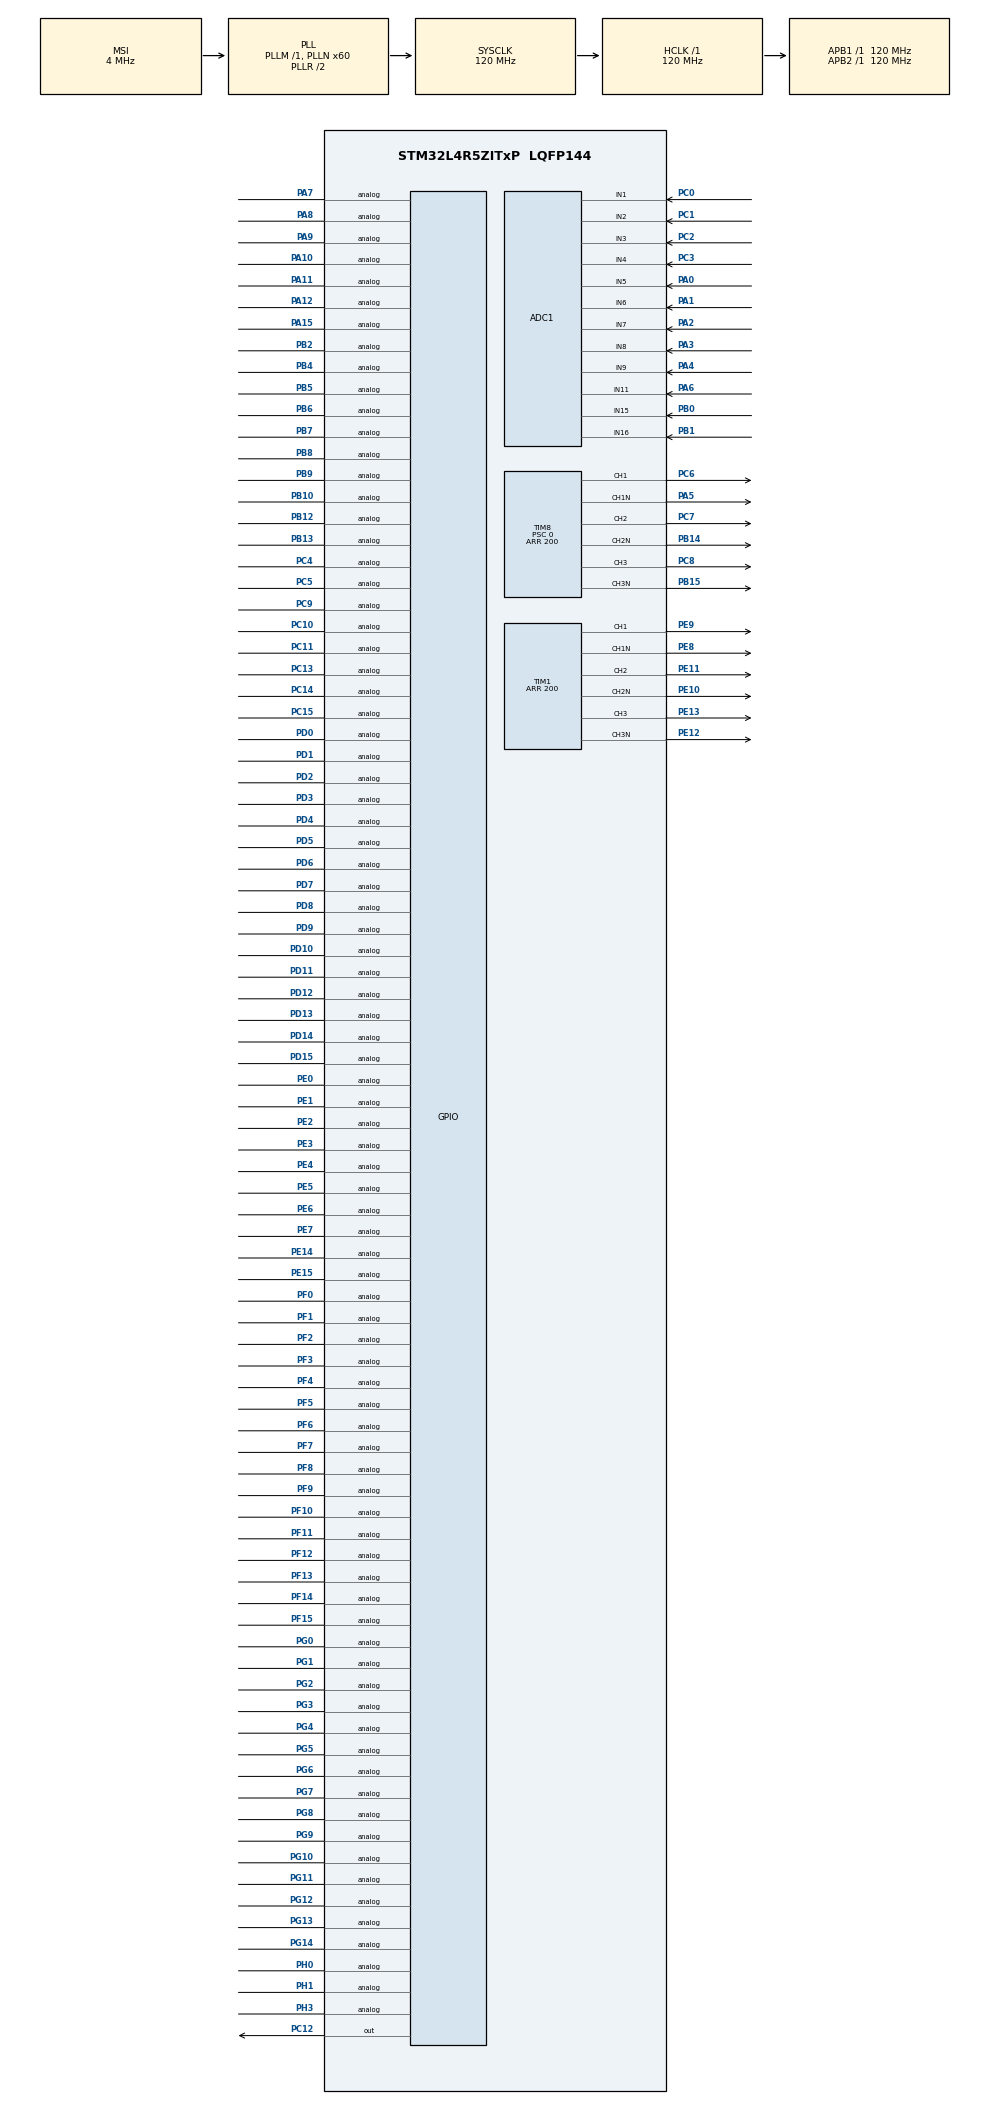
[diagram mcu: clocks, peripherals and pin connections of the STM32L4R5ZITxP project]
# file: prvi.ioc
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ADC1.Channel-0\#ChannelRegularConversion=ADC_CHANNEL_4
ADC1.Channel-1\#ChannelRegularConversion=ADC_CHANNEL_2
ADC1.Channel-2\#ChannelRegularConversion=ADC_CHANNEL_5
ADC1.Channel-3\#ChannelRegularConversion=ADC_CHANNEL_3
ADC1.Channel-4\#ChannelRegularConversion=ADC_CHANNEL_1
ADC1.ContinuousConvMode=ENABLE
ADC1.EOCSelection=ADC_EOC_SEQ_CONV
ADC1.EnableInjectedConversion=DISABLE
ADC1.ExternalTrigConv=ADC_EXTERNALTRIG_T1_TRGO2
ADC1.NbrOfConversion=5
ADC1.NbrOfConversionFlag=1
ADC1.OffsetNumber-0\#ChannelRegularConversion=ADC_OFFSET_NONE
ADC1.OffsetNumber-1\#ChannelRegularConversion=ADC_OFFSET_NONE
ADC1.OffsetNumber-2\#ChannelRegularConversion=ADC_OFFSET_NONE
ADC1.OffsetNumber-3\#ChannelRegularConversion=ADC_OFFSET_NONE
ADC1.OffsetNumber-4\#ChannelRegularConversion=ADC_OFFSET_NONE
ADC1.Overrun=ADC_OVR_DATA_OVERWRITTEN
ADC1.Rank-0\#ChannelRegularConversion=1
ADC1.Rank-1\#ChannelRegularConversion=2
ADC1.Rank-2\#ChannelRegularConversion=3
ADC1.Rank-3\#ChannelRegularConversion=4
ADC1.Rank-4\#ChannelRegularConversion=5
ADC1.Rank1_Channel=ADC_CHANNEL_2
ADC1.Rank2_Channel=ADC_CHANNEL_3
ADC1.Rank3_Channel=ADC_CHANNEL_4
ADC1.Rank4_Channel=ADC_CHANNEL_5
ADC1.SamplingTime-0\#ChannelRegularConversion=ADC_SAMPLETIME_2CYCLES_5
ADC1.SamplingTime-1\#ChannelRegularConversion=ADC_SAMPLETIME_2CYCLES_5
ADC1.SamplingTime-2\#ChannelRegularConversion=ADC_SAMPLETIME_6CYCLES_5
ADC1.SamplingTime-3\#ChannelRegularConversion=ADC_SAMPLETIME_6CYCLES_5
ADC1.SamplingTime-4\#ChannelRegularConversion=ADC_SAMPLETIME_6CYCLES_5
ADC1.master=1
Dma.ADC1.0.Direction=DMA_PERIPH_TO_MEMORY
Dma.ADC1.0.EventEnable=ENABLE
Dma.ADC1.0.Instance=DMA1_Channel1
Dma.ADC1.0.MemDataAlignment=DMA_MDATAALIGN_WORD
Dma.ADC1.0.MemInc=DMA_MINC_ENABLE
Dma.ADC1.0.Mode=DMA_NORMAL
Dma.ADC1.0.PeriphDataAlignment=DMA_PDATAALIGN_HALFWORD
Dma.ADC1.0.PeriphInc=DMA_PINC_DISABLE
Dma.ADC1.0.Polarity=HAL_DMAMUX_REQUEST_GEN_RISING
Dma.ADC1.0.Priority=DMA_PRIORITY_LOW
Dma.ADC1.0.RequestNumber=1
Dma.ADC1.0.SignalID=NONE
Dma.ADC1.0.SyncEnable=DISABLE
Dma.ADC1.0.SyncPolarity=HAL_DMAMUX_SYNC_NO_EVENT
Dma.ADC1.0.SyncRequestNumber=1
Dma.ADC1.0.SyncSignalID=NONE
Dma.Request0=ADC1
Mcu.Family=STM32L4
Mcu.Name=STM32L4R5ZITxP
Mcu.Package=LQFP144
NVIC.DMA1_Channel1_IRQn=true\:0\:0\:false\:false\:true\:false\:true
NVIC.DMAMUX1_OVR_IRQn=true\:0\:0\:false\:false\:true\:false\:false
NVIC.PriorityGroup=NVIC_PRIORITYGROUP_4
PA0.Signal=ADCx_IN5
PA1.Signal=ADCx_IN6
PA10.Signal=GPIO_Analog
PA11.Signal=GPIO_Analog
PA12.Signal=GPIO_Analog
PA13\ (JTMS/SWDIO).Mode=Trace_Asynchronous_SW
PA13\ (JTMS/SWDIO).Signal=SYS_JTMS-SWDIO
PA14\ (JTCK/SWCLK).Mode=Trace_Asynchronous_SW
PA14\ (JTCK/SWCLK).Signal=SYS_JTCK-SWCLK
PA15\ (JTDI).Signal=GPIO_Analog
PA2.Signal=ADCx_IN7
PA3.Signal=ADCx_IN8
PA4.Signal=ADCx_IN9
PA5.Mode=PWM Generation1 CH1 CH1N
PA5.Signal=TIM8_CH1N
PA6.Signal=ADCx_IN11
PA7.Signal=GPIO_Analog
PA8.Signal=GPIO_Analog
PA9.Signal=GPIO_Analog
PB0.Signal=ADCx_IN15
PB1.Signal=ADCx_IN16
PB10.Signal=GPIO_Analog
PB12.Signal=GPIO_Analog
PB13.Signal=GPIO_Analog
PB14.Mode=PWM Generation2 CH2 CH2N
PB14.Signal=TIM8_CH2N
PB15.Mode=PWM Generation3 CH3 CH3N
PB15.Signal=TIM8_CH3N
PB2.Signal=GPIO_Analog
PB3\ (JTDO/TRACESWO).Mode=Trace_Asynchronous_SW
PB3\ (JTDO/TRACESWO).Signal=SYS_JTDO-SWO
PB4\ (NJTRST).Signal=GPIO_Analog
PB5.Signal=GPIO_Analog
PB6.Signal=GPIO_Analog
PB7.Signal=GPIO_Analog
PB8.Signal=GPIO_Analog
PB9.Signal=GPIO_Analog
PC0.Signal=ADCx_IN1
PC1.Signal=ADCx_IN2
PC10.Signal=GPIO_Analog
PC11.Signal=GPIO_Analog
PC12.GPIO_Speed=GPIO_SPEED_FREQ_VERY_HIGH
PC12.Signal=GPIO_Output
PC13.Signal=GPIO_Analog
PC14-OSC32_IN\ (PC14).Signal=GPIO_Analog
PC15-OSC32_OUT\ (PC15).Signal=GPIO_Analog
PC2.Signal=ADCx_IN3
PC3.Signal=ADCx_IN4
PC4.Signal=GPIO_Analog
PC5.Signal=GPIO_Analog
PC6.Signal=S_TIM8_CH1
PC7.Signal=S_TIM8_CH2
PC8.Signal=S_TIM8_CH3
PC9.Signal=GPIO_Analog
PD0.Signal=GPIO_Analog
PD1.Signal=GPIO_Analog
PD10.Signal=GPIO_Analog
PD11.Signal=GPIO_Analog
PD12.Signal=GPIO_Analog
PD13.Signal=GPIO_Analog
PD14.Signal=GPIO_Analog
PD15.Signal=GPIO_Analog
PD2.Signal=GPIO_Analog
PD3.Signal=GPIO_Analog
PD4.Signal=GPIO_Analog
PD5.Signal=GPIO_Analog
PD6.Signal=GPIO_Analog
PD7.Signal=GPIO_Analog
PD8.Signal=GPIO_Analog
PD9.Signal=GPIO_Analog
PE0.Signal=GPIO_Analog
PE1.Signal=GPIO_Analog
PE10.Mode=PWM Generation2 CH2 CH2N
PE10.Signal=TIM1_CH2N
PE11.Signal=S_TIM1_CH2
PE12.Mode=PWM Generation3 CH3 CH3N
PE12.Signal=TIM1_CH3N
PE13.Signal=S_TIM1_CH3
PE14.Signal=GPIO_Analog
PE15.Signal=GPIO_Analog
PE2.Signal=GPIO_Analog
PE3.Signal=GPIO_Analog
PE4.Signal=GPIO_Analog
PE5.Signal=GPIO_Analog
PE6.Signal=GPIO_Analog
PE7.Signal=GPIO_Analog
PE8.Mode=PWM Generation1 CH1 CH1N
PE8.Signal=TIM1_CH1N
PE9.Signal=S_TIM1_CH1
PF0.Signal=GPIO_Analog
PF1.Signal=GPIO_Analog
PF10.Signal=GPIO_Analog
PF11.Signal=GPIO_Analog
PF12.Signal=GPIO_Analog
PF13.Signal=GPIO_Analog
PF14.Signal=GPIO_Analog
PF15.Signal=GPIO_Analog
PF2.Signal=GPIO_Analog
PF3.Signal=GPIO_Analog
PF4.Signal=GPIO_Analog
PF5.Signal=GPIO_Analog
PF6.Signal=GPIO_Analog
PF7.Signal=GPIO_Analog
PF8.Signal=GPIO_Analog
PF9.Signal=GPIO_Analog
PG0.Signal=GPIO_Analog
PG1.Signal=GPIO_Analog
PG10.Signal=GPIO_Analog
PG11.Signal=GPIO_Analog
PG12.Signal=GPIO_Analog
PG13.Signal=GPIO_Analog
PG14.Signal=GPIO_Analog
PG2.Signal=GPIO_Analog
PG3.Signal=GPIO_Analog
PG4.Signal=GPIO_Analog
PG5.Signal=GPIO_Analog
PG6.Signal=GPIO_Analog
PG7.Signal=GPIO_Analog
PG8.Signal=GPIO_Analog
PG9.Signal=GPIO_Analog
PH0-OSC_IN\ (PH0).Signal=GPIO_Analog
PH1-OSC_OUT\ (PH1).Signal=GPIO_Analog
PH3-BOOT0.Signal=GPIO_Analog
ProjectManager.HeapSize=0x200
ProjectManager.StackSize=0x400
ProjectManager.TargetToolchain=STM32CubeIDE
RCC.ADCFreq_Value=74000000
RCC.AHBFreq_Value=120000000
RCC.APB1Freq_Value=120000000
RCC.APB1TimFreq_Value=120000000
RCC.APB2Freq_Value=120000000
RCC.APB2TimFreq_Value=120000000
RCC.CortexFreq_Value=120000000
RCC.HCLKFreq_Value=120000000
RCC.HSE_VALUE=8000000
RCC.HSI48_VALUE=48000000
RCC.HSI_VALUE=16000000
RCC.LSE_VALUE=32768
RCC.MSI_VALUE=4000000
RCC.PLLN=60
RCC.PLLSAI1N=37
RCC.SYSCLKFreq_VALUE=120000000
RCC.SYSCLKSource=RCC_SYSCLKSOURCE_PLLCLK
RCC.USBFreq_Value=74000000
RCC.VCOOutputFreq_Value=240000000
SH.ADCx_IN1.0=ADC1_IN1,IN1-Single-Ended
SH.ADCx_IN11.0=ADC1_IN11,IN11-Single-Ended
SH.ADCx_IN15.0=ADC1_IN15,IN15-Single-Ended
SH.ADCx_IN16.0=ADC1_IN16,IN16-Single-Ended
SH.ADCx_IN2.0=ADC1_IN2,IN2-Single-Ended
SH.ADCx_IN3.0=ADC1_IN3,IN3-Single-Ended
SH.ADCx_IN4.0=ADC1_IN4,IN4-Single-Ended
SH.ADCx_IN5.0=ADC1_IN5,IN5-Single-Ended
SH.ADCx_IN6.0=ADC1_IN6,IN6-Single-Ended
SH.ADCx_IN7.0=ADC1_IN7,IN7-Single-Ended
SH.ADCx_IN8.0=ADC1_IN8,IN8-Single-Ended
SH.ADCx_IN9.0=ADC1_IN9,IN9-Single-Ended
SH.S_TIM1_CH1.0=TIM1_CH1,PWM Generation1 CH1 CH1N
SH.S_TIM1_CH2.0=TIM1_CH2,PWM Generation2 CH2 CH2N
SH.S_TIM1_CH3.0=TIM1_CH3,PWM Generation3 CH3 CH3N
SH.S_TIM8_CH1.0=TIM8_CH1,PWM Generation1 CH1 CH1N
SH.S_TIM8_CH2.0=TIM8_CH2,PWM Generation2 CH2 CH2N
SH.S_TIM8_CH3.0=TIM8_CH3,PWM Generation3 CH3 CH3N
TIM1.AutoReloadPreload=TIM_AUTORELOAD_PRELOAD_ENABLE
TIM1.Channel-PWM\ Generation1\ CH1\ CH1N=TIM_CHANNEL_1
TIM1.Channel-PWM\ Generation2\ CH2\ CH2N=TIM_CHANNEL_2
TIM1.Channel-PWM\ Generation3\ CH3\ CH3N=TIM_CHANNEL_3
TIM1.CounterMode=TIM_COUNTERMODE_CENTERALIGNED2
TIM1.DeadTime=12
TIM1.OCFastMode_PWM-PWM\ Generation1\ CH1\ CH1N=TIM_OCFAST_ENABLE
TIM1.OCFastMode_PWM-PWM\ Generation2\ CH2\ CH2N=TIM_OCFAST_ENABLE
TIM1.OCFastMode_PWM-PWM\ Generation3\ CH3\ CH3N=TIM_OCFAST_ENABLE
TIM1.OCMode_PWM-PWM\ Generation1\ CH1\ CH1N=TIM_OCMODE_PWM1
TIM1.OCMode_PWM-PWM\ Generation2\ CH2\ CH2N=TIM_OCMODE_PWM1
TIM1.OCMode_PWM-PWM\ Generation3\ CH3\ CH3N=TIM_OCMODE_PWM1
TIM1.Period=200
TIM1.Pulse-PWM\ Generation1\ CH1\ CH1N=40
TIM1.Pulse-PWM\ Generation2\ CH2\ CH2N=160
TIM1.Pulse-PWM\ Generation3\ CH3\ CH3N=110
TIM1.TIM_MasterOutputTrigger2=TIM_TRGO2_UPDATE
TIM8.AutoReloadPreload=TIM_AUTORELOAD_PRELOAD_ENABLE
TIM8.Channel-PWM\ Generation1\ CH1\ CH1N=TIM_CHANNEL_1
TIM8.Channel-PWM\ Generation2\ CH2\ CH2N=TIM_CHANNEL_2
TIM8.Channel-PWM\ Generation3\ CH3\ CH3N=TIM_CHANNEL_3
TIM8.CounterMode=TIM_COUNTERMODE_CENTERALIGNED2
TIM8.DeadTime=12
TIM8.OCFastMode_PWM-PWM\ Generation1\ CH1\ CH1N=TIM_OCFAST_ENABLE
TIM8.OCFastMode_PWM-PWM\ Generation2\ CH2\ CH2N=TIM_OCFAST_ENABLE
TIM8.OCFastMode_PWM-PWM\ Generation3\ CH3\ CH3N=TIM_OCFAST_ENABLE
TIM8.Period=200
TIM8.Prescaler=0
TIM8.Pulse-PWM\ Generation1\ CH1\ CH1N=150
TIM8.Pulse-PWM\ Generation2\ CH2\ CH2N=250
TIM8.Pulse-PWM\ Generation3\ CH3\ CH3N=167
VP_TIM1_VS_ClockSourceINT.Mode=Internal
board=NUCLEO-L4R5ZI-P

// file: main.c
/* USER CODE BEGIN Header */

/*
 * drolja sa frekvencijom regulacije 25KHz za ulazne i bat, a 12.5KHz za izlazne
 * svaka prekidna je podeljena na 3 dela: priprema ADC, usrednjavanje izmerenog, regulacija
 * prekidnu uvek zove DMA, a koja se prekidna izvrsava se odlucuje pomocu brojaca dma_cnt
 */

/* USER CODE END Header */

#include "main.h"

ADC_HandleTypeDef hadc1;
DMA_HandleTypeDef hdma_adc1;

TIM_HandleTypeDef htim1;
TIM_HandleTypeDef htim8;

/* USER CODE BEGIN PV */

volatile int dma_cnt = 0, i1=0, i2=0;
volatile float v_pv1, i_pv1, vold_pv1 = 0, iold_pv1 = 0, e_pv1, eold_pv1 = 0, d_pv1, dold_pv1 = 0.8, p_pv1, pold_pv1 = 0;			//za prvi ulazni buck
volatile float v_pv2, i_pv2, vold_pv2 = 0, iold_pv2 = 0, e_pv2, eold_pv2 = 0, d_pv2, dold_pv2 = 0.8, p_pv2, pold_pv2 = 0;			//za drugi ulazni buck
volatile float v_dc;																												//za link
volatile float v_5v, e_5v, eold_5v = 0, d_5v, dold_5v = 0.835;																		//za 5v izlaz
volatile float v_3v3, e_3v3, eold_3v3 = 0, d_3v3, dold_3v3 = 0.55;																	//za 3v3 izlaz
volatile float v_bat, i_bat, e_bat, eold_bat = 0, d_bat, dold_bat = 0.75;															//za bateriju

volatile int zaokruzi;
volatile float step;
const float step_mppt = 0.0002;

//koeficijenti za razdelnike - svi podlozni promenama
const float v_dc_coef = 0.0026333;			//0-9V
const float v_pv_coef = 0.00629;			//0-25V
const float i_pv_coef = 0.0004884;			//?????
const float v_3v3_coef = 0.0018156;			//0-6.6V
const float v_5v_coef = 0.0022055;			//0-8V

//koeficijenti za regulaciju
const float reg1_3v3 = 0.002;
const float reg2_3v3 = 0.001;
const float reg1_5v = 0.002;
const float reg2_5v = 0.001;
const float reg1_bat = 0.002;
const float reg2_bat = 0.001;
const float reg_pv = 0.005;				//za pv pomeranje
const float ref_3v3 = 3.3;					//referenca koja ne moze da se upise sa vmov

//bufferi za DMA:
uint32_t pv1_buffer[40], pv2_buffer[40], bat_buffer[24], out3v3_buffer[16], out5v_buffer[16];

/* USER CODE END PV */

void SystemClock_Config(void);
static void MX_GPIO_Init(void);
static void MX_DMA_Init(void);
static void MX_ADC1_Init(void);
static void MX_TIM1_Init(void);
static void MX_TIM8_Init(void);

/* USER CODE BEGIN 0 */

void DMA1_Channel1_IRQHandler(void)
{
	if (DMA1 -> ISR & 2) {							//transfer complete se obradjuje
		DMA1 -> IFCR = 2;

		ADC1 -> CR |= 0x10;							//ADC stop (mora OR a ne dodela da se ne bi pojebala kalibracija
		DMA1_Channel1 -> CCR &= 0xFFFFFFFE;			//disable DMA

    	dma_cnt++;									//uvecaj brojac radi pracenja u kojoj si prekidnoj

		while (DMA1_Channel1 -> CCR & 1);			//cekaj disable
		//while (ADC1 -> CR & 4);	//nije neophodno cekati da se adc stopira jer ima dosta instrukcija izmedju

		/* KORISTAN DEO KODA */
		switch (dma_cnt) {								//provera u kojoj smo prekidnoj

		/* pv1 */
		case 1:
		case 5:
			/* priprema sledeceg merenja */
			DMA1_Channel1 -> CMAR = (int) bat_buffer;	//postavi buffer za upis
			DMA1_Channel1 -> CNDTR = 24;				//koliko upisa
			ADC1 -> SQR1 = 0x001C8142;					//kanali 5,8,7 (Udc, Ub, Ib)
			DMA1_Channel1 -> CCR |= 1;					//enable DMA
		    ADC1 -> CR |= 0x4;							//ADC start
			/* kraj pripreme merenja */

			/* usrednjavanje */
			v_dc  = (pv1_buffer[2] + pv1_buffer[7] + pv1_buffer[12] + pv1_buffer[17] + pv1_buffer[22] + pv1_buffer[27] + pv1_buffer[32] + pv1_buffer[37])>>3;
			asm("ldr r0, =v_dc;"
					"ldr r1, [r0];"
			  		"ldr r2, =v_dc_coef;"
			  		"ldr r3, [r2];"
			   		"vmov s2, r1;"
			   		"vmov s4, r3;"
			   		"vmul.f32 s2, s2, s4;"
			   		"vmov r1, s2;"
			   		"str r1, [r0]");
			v_pv1 = (pv1_buffer[1] + pv1_buffer[6] + pv1_buffer[11] + pv1_buffer[16] + pv1_buffer[21] + pv1_buffer[26] + pv1_buffer[31] + pv1_buffer[36])>>3;
			asm("ldr r0, =v_pv1;"
			   		"ldr r1, [r0];"
			  		"ldr r2, =v_pv_coef;"
			   		"ldr r3, [r2];"
			   		"vmov s2, r1;"
			   		"vmov s4, r3;"
			   		"vmul.f32 s2, s2, s4;"
			   		"vmov r1, s2;"
			   		"str r1, [r0]");
			v_pv2 = (pv1_buffer[0] + pv1_buffer[5] + pv1_buffer[10] + pv1_buffer[15] + pv1_buffer[20] + pv1_buffer[25] + pv1_buffer[30] + pv1_buffer[35])>>3;
			asm("ldr r0, =v_pv2;"
			   		"ldr r1, [r0];"
			  		"ldr r2, =v_pv_coef;"
			   		"ldr r3, [r2];"
			   		"vmov s2, r1;"
			   		"vmov s4, r3;"
			   		"vmul.f32 s2, s2, s4;"
			   		"vmov r1, s2;"
			   		"str r1, [r0]");
			i_pv1 = (pv1_buffer[4] + pv1_buffer[9] + pv1_buffer[14] + pv1_buffer[19] + pv1_buffer[24] + pv1_buffer[29] + pv1_buffer[34] + pv1_buffer[39])>>3;
			asm("ldr r0, =i_pv1;"
			   		"ldr r1, [r0];"
			  		"ldr r2, =i_pv_coef;"
			   		"ldr r3, [r2];"
			   		"vmov s2, r1;"
			   		"vmov s4, r3;"
			   		"vmul.f32 s2, s2, s4;"
			   		"vmov r1, s2;"
			   		"str r1, [r0]");
			i_pv2 = (pv1_buffer[3] + pv1_buffer[8] + pv1_buffer[13] + pv1_buffer[18] + pv1_buffer[23] + pv1_buffer[28] + pv1_buffer[33] + pv1_buffer[38])>>3;
			asm("ldr r0, =i_pv2;"
			   		"ldr r1, [r0];"
			  		"ldr r2, =i_pv_coef;"
			   		"ldr r3, [r2];"
			   		"vmov s2, r1;"
			   		"vmov s4, r3;"
			   		"vmul.f32 s2, s2, s4;"
			   		"vmov r1, s2;"
			   		"str r1, [r0]");
			/* kraj usrednjavanja */

			/* regulacija */

			/* PV POMERANJE */

//			//brze ovako nego asm
//		if(i1==0){
//			e_pv1 = 6.0 - v_dc;
//
//			//step = 0.00005 * e_pv1;
//			asm("ldr r0, =step;"
//					"ldr r2, =reg_pv;"
//					"ldr r4, =e_pv1;"
//					"ldr r3, [r2];"
//					"ldr r5, [r4];"
//					"vmov s4, r3;"
//					"vmov s2, r5;"
//					"vmul.f32 s2, s2, s4;"
//					"vmov r1, s2;"
//					"str r1, [r0]");
//
//			//p_pv1 = i_pv1 * v_pv1;
//			asm("ldr r0, =p_pv1;"
//					"ldr r2, =i_pv1;"
//					"ldr r4, =v_pv1;"
//					"ldr r3, [r2];"
//					"ldr r5, [r4];"
//					"vmov s4, r3;"
//					"vmov s2, r5;"
//					"vmul.f32 s2, s2, s4;"
//					"vmov r1, s2;"
//					"str r1, [r0]");
//
//			if (p_pv1 > pold_pv1) {
//				if (v_pv1 > vold_pv1) {
//					d_pv1 = dold_pv1 - step;
//				}
//				else {
//					d_pv1 = dold_pv1 + 0.01;
//				}
//			}
//			else {
//				if (v_pv1 < vold_pv1) {
//					d_pv1 = dold_pv1 - step;
//				}
//				else {
//					d_pv1 = dold_pv1 + 0.01;
//				}
//			}
//
//			//ogranicavanje djutija
//			if (d_pv1 > 0.9) d_pv1 = 0.9;
//			else if (d_pv1 < 0.2) d_pv1 = 0.2;
//
//			//ovo je brze ovako nego u asm
//			zaokruzi = (volatile int) (d_pv1 * 200);
//			if (d_pv1 * 200 - zaokruzi >= 0.5f) zaokruzi++;
//			TIM1 -> CCR1 = zaokruzi;
//
//			dold_pv1 = d_pv1;
//			pold_pv1 = p_pv1;
//			vold_pv1 = v_pv1;
//			i1=0;
//			}else{
//				i1++;
//			}

			/* MPPT */

//			//p_pv1 = i_pv1 * v_pv1;
//			asm("ldr r0, =p_pv1;"
//					"ldr r2, =i_pv1;"
//					"ldr r4, =v_pv1;"
//					"ldr r3, [r2];"
//					"ldr r5, [r4];"
//					"vmov s4, r3;"
//					"vmov s2, r5;"
//					"vmul.f32 s2, s2, s4;"
//					"vmov r1, s2;"
//					"str r1, [r0]");
//
//			if (i_pv1 < 0.001 && v_pv1 > 0) {
//				//d_pv1 = dold_pv1 + 100 * step_mppt;
//				d_pv1 = dold_pv1 + 0.01;
//			}
//			else {
//				if (p_pv1 > pold_pv1) {
//					if (v_pv1 > vold_pv1) d_pv1 = dold_pv1 - step_mppt;
//					else d_pv1 = dold_pv1 + step_mppt;
//				}
//				else {
//					if (v_pv1 < vold_pv1) d_pv1 = dold_pv1 - step_mppt;
//					else d_pv1 = dold_pv1 + step_mppt;
//				}
//			}
//
//			//ogranicavanje djutija
//			if (d_pv1 > 0.9) d_pv1 = 0.9;
//			else if (d_pv1 < 0.1) d_pv1 = 0.1;
//
//			//ovo je brze ovako nego u asm
//			zaokruzi = (volatile int) (d_pv1 * 200);
//			if (d_pv1 * 200 - zaokruzi > 0.5f) zaokruzi++;
//			TIM1 -> CCR1 = zaokruzi;
//
//			dold_pv1 = d_pv1;
//			pold_pv1 = p_pv1;
//			vold_pv1 = v_pv1;

			/* kraj regulacije */

 			break;

		/* baterija */
		case 2:
		case 6:
			/* priprema sledeceg merenja */
			DMA1_Channel1 -> CMAR = (int) pv2_buffer;	//postavi buffer za upis
			DMA1_Channel1 -> CNDTR = 40;				//koliko upisa
			ADC1 -> SQR1 = 0x01144084;					//kanali 2,4,5,1,3 (Upv1, Upv2, Udc, Ipv1, Ipv2)
			ADC1 -> SQR2 = 0x00000003;
			DMA1_Channel1 -> CCR |= 1;					//enable DMA
		    ADC1 -> CR |= 0x4;							//ADC start
			/* kraj pripreme merenja */

		    /* usrednjavanje */
			v_dc = (bat_buffer[0] + bat_buffer[3] + bat_buffer[6] + bat_buffer[9] + bat_buffer[12] + bat_buffer[15] + bat_buffer[18] + bat_buffer[21])>>3;
			asm("ldr r0, =v_dc;"
					"ldr r1, [r0];"
					"ldr r2, =v_dc_coef;"
					"ldr r3, [r2];"
					"vmov s2, r1;"
					"vmov s4, r3;"
					"vmul.f32 s2, s2, s4;"
					"vmov r1, s2;"
					"str r1, [r0]");

			//FALI USREDNJAVANJE NAPONA I STRUJE BATERIJE

			/* kraj usrednjavanja */

			/* regulacija */
////			e_bat = 6.0 - v_dc;
//			asm("ldr r0, =e_bat;"
//					"vmov.f32 s2, #6.0;"
//					"ldr r2, =v_dc;"
//					"ldr r3, [r2];"
//					"vmov s4, r3;"
//					"vsub.f32 s2, s2, s4;"
//					"vmov r1, s2;"
//					"str r1, [r0]");
//
////			d_bat = dold_bat + 0.002 * e_bat - 0.001 * eold_bat;
//			asm("ldr r0, =d_bat;"
//					"ldr r2, =dold_bat;"
//					"ldr r4, =e_bat;"
//					"ldr r6, =reg1_bat;"
//					"ldr r1, [r2];"
//					"ldr r3, [r4];"
//					"ldr r5, [r6];"
//					"vmov s1, r1;"
//					"vmov s3, r3;"
//					"vmov s5, r5;"
//					"vmul.f32 s3, s3, s5;"
//					"vadd.f32 s1, s1, s3;"
//					"ldr r4, =eold_bat;"
//					"ldr r6, =reg2_bat;"
//					"ldr r3, [r4];"
//					"ldr r5, [r6];"
//					"vmov s3, r3;"
//					"vmov s5, r5;"
//					"vmul.f32 s3, s3, s5;"
//					"vsub.f32 s1, s1, s3;"
//					"vmov r1, s1;"
//					"str r1, [r0]");
//
//			if (d_bat > 0.9) d_bat = 0.9;
//			else if (d_bat < 0.1) d_bat = 0.1;
//
//			//ovo je brze ovako nego u asm
//			zaokruzi = (volatile int) (d_bat * 200);
//			if (d_bat * 200 - zaokruzi > 0.5f) zaokruzi++;
//			TIM8 -> CCR1 = zaokruzi;						//ovo je D za boost, ne treba ovako, nego treba ovde da se upisuje u CCR2
//
//			eold_bat = e_bat;
//			dold_bat = d_bat;

			/* kraj regulacije */

			break;

		/* pv2 */
		case 3:
		case 7:
			/* priprema sledeceg merenja */
			if (dma_cnt == 3) {
				DMA1_Channel1 -> CMAR = (int) out5v_buffer;		//postavi buffer za upis
				ADC1 -> SQR1 = 0x10410403;						//kanal 16,16,16,16 (U5v)
			}
			else {
				DMA1_Channel1 -> CMAR = (int) out3v3_buffer;	//postavi buffer za upis
				ADC1 -> SQR1 = 0x0B2CB2C3;						//kanal 11,11,11,11 (U3v3)
			}
			DMA1_Channel1 -> CNDTR = 16;				//koliko upisa
			DMA1_Channel1 -> CCR |= 1;					//enable DMA
		    ADC1 -> CR |= 0x4;							//ADC start
			/* kraj pripreme merenja */

			/* usrednjavanje */
		    v_dc = (pv2_buffer[2] + pv2_buffer[7] + pv2_buffer[12] + pv2_buffer[17] + pv2_buffer[22] + pv2_buffer[27] + pv2_buffer[32] + pv2_buffer[37])>>3;
			asm("ldr r0, =v_dc;"
					"ldr r1, [r0];"
					"ldr r2, =v_dc_coef;"
					"ldr r3, [r2];"
					"vmov s2, r1;"
					"vmov s4, r3;"
					"vmul.f32 s2, s2, s4;"
					"vmov r1, s2;"
					"str r1, [r0]");
			v_pv2 = (pv2_buffer[1] + pv2_buffer[6] + pv2_buffer[11] + pv2_buffer[16] + pv2_buffer[21] + pv2_buffer[26] + pv2_buffer[31] + pv2_buffer[36])>>3;
			asm("ldr r0, =v_pv2;"
					"ldr r1, [r0];"
					"ldr r2, =v_pv_coef;"
					"ldr r3, [r2];"
					"vmov s2, r1;"
					"vmov s4, r3;"
					"vmul.f32 s2, s2, s4;"
					"vmov r1, s2;"
					"str r1, [r0]");
			v_pv1 = (pv2_buffer[0] + pv2_buffer[5] + pv2_buffer[10] + pv2_buffer[15] + pv2_buffer[20] + pv2_buffer[25] + pv2_buffer[30] + pv2_buffer[35])>>3;
			asm("ldr r0, =v_pv1;"
					"ldr r1, [r0];"
					"ldr r2, =v_pv_coef;"
					"ldr r3, [r2];"
					"vmov s2, r1;"
					"vmov s4, r3;"
					"vmul.f32 s2, s2, s4;"
					"vmov r1, s2;"
					"str r1, [r0]");
			i_pv2 = (pv2_buffer[4] + pv2_buffer[9] + pv2_buffer[14] + pv2_buffer[19] + pv2_buffer[24] + pv2_buffer[29] + pv2_buffer[34] + pv2_buffer[39])>>3;
			asm("ldr r0, =i_pv2;"
					"ldr r1, [r0];"
					"ldr r2, =i_pv_coef;"
					"ldr r3, [r2];"
					"vmov s2, r1;"
					"vmov s4, r3;"
					"vmul.f32 s2, s2, s4;"
					"vmov r1, s2;"
					"str r1, [r0]");
			i_pv1 = (pv2_buffer[3] + pv2_buffer[8] + pv2_buffer[13] + pv2_buffer[18] + pv2_buffer[23] + pv2_buffer[28] + pv2_buffer[33] + pv2_buffer[38])>>3;
			asm("ldr r0, =i_pv1;"
					"ldr r1, [r0];"
					"ldr r2, =i_pv_coef;"
					"ldr r3, [r2];"
					"vmov s2, r1;"
					"vmov s4, r3;"
					"vmul.f32 s2, s2, s4;"
					"vmov r1, s2;"
					"str r1, [r0]");
			/* kraj usrednjavanja */

			/* regulacija */

			/* PV POMERANJE */

//			if(i2==0){
//			//brze ovako nego asm
//			e_pv2 = 6.0 - v_dc;
//
//			//step = 0.00005 * e_pv2;
//			asm("ldr r0, =step;"
//					"ldr r2, =reg_pv;"
//					"ldr r4, =e_pv2;"
//					"ldr r3, [r2];"
//					"ldr r5, [r4];"
//					"vmov s4, r3;"
//					"vmov s2, r5;"
//					"vmul.f32 s2, s2, s4;"
//					"vmov r1, s2;"
//					"str r1, [r0]");
//
////			p_pv2 = i_pv2 * v_pv2;
//			asm("ldr r0, =p_pv2;"
//					"ldr r2, =i_pv2;"
//					"ldr r4, =v_pv2;"
//					"ldr r3, [r2];"
//					"ldr r5, [r4];"
//					"vmov s4, r3;"
//					"vmov s2, r5;"
//					"vmul.f32 s2, s2, s4;"
//					"vmov r1, s2;"
//					"str r1, [r0]");
//
//			if (p_pv2 > pold_pv2) {
//				if (v_pv2 > vold_pv2) {
//					d_pv2 = dold_pv2 - step;
//				}
//				else {
//					d_pv2 = dold_pv2 + 0.01;
//				}
//			}
//			else {
//				if (v_pv2 < vold_pv2) {
//					d_pv2 = dold_pv2 - step;
//				}
//				else {
//					d_pv2 = dold_pv2 + 0.01;
//				}
//			}
//
//			if (d_pv2 > 0.9) d_pv2 = 0.9;
//			else if (d_pv2 < 0.2) d_pv2 = 0.2;
//
//			//ovo je brze ovako nego u asm
//			zaokruzi = (volatile int) (d_pv2 * 200);
//			if (d_pv2 * 200 - zaokruzi > 0.5f) zaokruzi++;
//			TIM1 -> CCR2 = 200 - zaokruzi;
//
//			dold_pv2 = d_pv2;
//			pold_pv2 = p_pv2;
//			vold_pv2 = v_pv2;
//			i2=0;
//			}else{
//				i2++;
//			}

			/* MPPT */

////			p_pv2 = i_pv2 * v_pv2;
//			asm("ldr r0, =p_pv2;"
//					"ldr r2, =i_pv2;"
//					"ldr r4, =v_pv2;"
//					"ldr r3, [r2];"
//					"ldr r5, [r4];"
//					"vmov s4, r3;"
//					"vmov s2, r5;"
//					"vmul.f32 s2, s2, s4;"
//					"vmov r1, s2;"
//					"str r1, [r0]");
//
//			if (i_pv2 < 0.001 && v_pv2 > 0) {
//				//d_pv2 = dold_pv2 + 100 * step_mppt;
//				d_pv2 = dold_pv2 + 0.01;
//			}
//			else {
//				if (p_pv2 > pold_pv2) {
//					if (v_pv2 > vold_pv2) d_pv2 = dold_pv2 - step_mppt;
//					else d_pv2 = dold_pv2 + step_mppt;
//				}
//				else {
//					if (v_pv2 < vold_pv2) d_pv2 = dold_pv2 - step_mppt;
//					else d_pv2 = dold_pv2 + step_mppt;
//				}
//			}
//
//			//ogranicavanje djutija
//			if (d_pv2 > 0.9) d_pv2 = 0.9;
//			else if (d_pv2 < 0.1) d_pv2 = 0.1;
//
//			//ovo je brze ovako nego u asm
//			zaokruzi = (volatile int) (d_pv2 * 200);
//			if (d_pv2 * 200 - zaokruzi > 0.5f) zaokruzi++;
//			TIM1 -> CCR2 = 200 - zaokruzi;
//
//			dold_pv2 = d_pv2;
//			pold_pv2 = p_pv2;
//			vold_pv2 = v_pv2;

			/* kraj regulacije */

			break;

		/* out 5V */
		case 4:
			/* priprema sledeceg merenja */
			DMA1_Channel1 -> CMAR = (int) pv1_buffer;	//postavi buffer za upis
			DMA1_Channel1 -> CNDTR = 40;				//koliko upisa
			ADC1 -> SQR1 = 0x03142104;					//kanali 4,2,5,3,1 (Upv2, Upv1, Udc, Ipv2, Ipv1)
			ADC1 -> SQR2 = 0x00000001;
			DMA1_Channel1 -> CCR |= 1;					//enable DMA
		    ADC1 -> CR |= 0x4;							//ADC start
			/* kraj pripreme merenja */

		    /* usrednjavanje */
			v_5v = (out5v_buffer[8] + out5v_buffer[9] + out5v_buffer[10] + out5v_buffer[11] + out5v_buffer[12] + out5v_buffer[13] + out5v_buffer[14] + out5v_buffer[15])>>3;
			asm("ldr r0, =v_5v;"
					"ldr r1, [r0];"
					"ldr r2, =v_5v_coef;"
					"ldr r3, [r2];"
					"vmov s2, r1;"
					"vmov s4, r3;"
					"vmul.f32 s2, s2, s4;"
					"vmov r1, s2;"
					"str r1, [r0]");
			/* kraj usrednjavanja */

			/* regulacija */
//			e_5v = 5.0 - v_5v;
			asm("ldr r0, =e_5v;"
					"vmov.f32 s2, #5.0;"
					"ldr r2, =v_5v;"
					"ldr r3, [r2];"
					"vmov s4, r3;"
					"vsub.f32 s2, s2, s4;"
					"vmov r1, s2;"
					"str r1, [r0]");

			if (e_5v < 0.03 && e_5v > -0.03) e_5v = 0;

//			d_5v = dold_5v + 0.002 * e_5v - 0.001 * eold_5v;
			asm("ldr r0, =d_5v;"
					"ldr r2, =dold_5v;"
					"ldr r4, =e_5v;"
					"ldr r6, =reg1_5v;"
					"ldr r1, [r2];"
					"ldr r3, [r4];"
					"ldr r5, [r6];"
					"vmov s1, r1;"
					"vmov s3, r3;"
					"vmov s5, r5;"
					"vmul.f32 s3, s3, s5;"
					"vadd.f32 s1, s1, s3;"
					"ldr r4, =eold_5v;"
					"ldr r6, =reg2_5v;"
					"ldr r3, [r4];"
					"ldr r5, [r6];"
					"vmov s3, r3;"
					"vmov s5, r5;"
					"vmul.f32 s3, s3, s5;"
					"vsub.f32 s1, s1, s3;"
					"vmov r1, s1;"
					"str r1, [r0]");

			if (d_5v > 0.9) d_5v = 0.9;
			else if (d_5v < 0.1) d_5v = 0.1;

			//ovo je brze ovako nego u asm
			zaokruzi = (volatile int) (d_5v * 200);
			if (d_5v * 200 - zaokruzi >= 0.5f) zaokruzi++;
			TIM8 -> CCR3 = zaokruzi;

			eold_5v = e_5v;
			dold_5v = d_5v;
			/* kraj regulacije */

			break;

		/* out 3V3 */
		case 8:
			/* priprema sledeceg merenja */
			DMA1_Channel1 -> CMAR = (int) pv1_buffer;	//postavi buffer za upis
			DMA1_Channel1 -> CNDTR = 40;				//koliko upisa
			ADC1 -> SQR1 = 0x03142104;					//kanali 4,2,5,3,1 (Upv2, Upv1, Udc, Ipv2, Ipv1)
			ADC1 -> SQR2 = 0x00000001;
			DMA1_Channel1 -> CCR |= 1;					//enable DMA
		    ADC1 -> CR |= 0x4;							//ADC start
			/* kraj pripreme merenja */

			/* usrednjavanje */
			v_3v3 = (out3v3_buffer[8] + out3v3_buffer[9] + out3v3_buffer[10] + out3v3_buffer[11] + out3v3_buffer[12] + out3v3_buffer[13] + out3v3_buffer[14] + out3v3_buffer[15])>>3;
			asm("ldr r0, =v_3v3;"
			   		"ldr r1, [r0];"
			  		"ldr r2, =v_3v3_coef;"
			   		"ldr r3, [r2];"
			   		"vmov s2, r1;"
			   		"vmov s4, r3;"
			   		"vmul.f32 s2, s2, s4;"
			   		"vmov r1, s2;"
			   		"str r1, [r0]");
			/* kraj usrednjavanja */

			/* regulacija */
//			e_3v3 = 3.3 - v_3v3;
			asm("ldr r0, =e_3v3;"
					"ldr r4, =ref_3v3;"
					"ldr r2, =v_3v3;"
					"ldr r1, [r2];"
					"ldr r3, [r4];"
					"vmov s4, r1;"
					"vmov s2, r3;"
					"vsub.f32 s2, s2, s4;"
					"vmov r1, s2;"
					"str r1, [r0]");

			if (e_3v3 < 0.03 && e_3v3 > -0.03) e_3v3 = 0;

//			d_3v3 = dold_3v3 + 0.002 * e_3v3 - 0.001 * eold_3v3;
			asm("ldr r0, =d_3v3;"
					"ldr r2, =dold_3v3;"
					"ldr r4, =e_3v3;"
					"ldr r6, =reg1_3v3;"
					"ldr r1, [r2];"
					"ldr r3, [r4];"
					"ldr r5, [r6];"
					"vmov s1, r1;"
					"vmov s3, r3;"
					"vmov s5, r5;"
					"vmul.f32 s3, s3, s5;"
					"vadd.f32 s1, s1, s3;"
					"ldr r4, =eold_3v3;"
					"ldr r6, =reg2_3v3;"
					"ldr r3, [r4];"
					"ldr r5, [r6];"
					"vmov s3, r3;"
					"vmov s5, r5;"
					"vmul.f32 s3, s3, s5;"
					"vsub.f32 s1, s1, s3;"
					"vmov r1, s1;"
					"str r1, [r0]");

			if (d_3v3 > 0.9) d_3v3 = 0.9;
			else if (d_3v3 < 0.1) d_3v3 = 0.1;

			//ovo je brze ovako nego u asm
			zaokruzi = (volatile int) (d_3v3 * 200);
			if (d_3v3 * 200 - zaokruzi >= 0.5f) zaokruzi++;
			TIM1 -> CCR3 = zaokruzi;

			eold_3v3 = e_3v3;
			dold_3v3 = d_3v3;
			/* kraj regulacije */

			dma_cnt = 0;
			break;
		}
		/* KRAJ KORISNOG DELA KODA */

	}
	else {

		if (DMA1 -> ISR & 4) {						//half transfer se ignorise
			DMA1 -> IFCR = 4;

			while (DMA1 -> ISR & 4);
		}
		else {										//transfer error upali DMA opet
			DMA1 -> IFCR = 8;

			DMA1_Channel1 -> CCR |= 1;				//enable
		}
	}
}

/* USER CODE END 0 */

int main(void)
{

  /* MCU Configuration--------------------------------------------------------*/

  /* Reset of all peripherals, Initializes the Flash interface and the Systick. */
  HAL_Init();

  /* Configure the system clock */
  SystemClock_Config();

  /* Initialize all configured peripherals */
  MX_GPIO_Init();
  MX_DMA_Init();
  MX_ADC1_Init();
  MX_TIM1_Init();
  MX_TIM8_Init();
  /* USER CODE BEGIN 2 */

  //postavljanje brzine kanala
  LL_ADC_SetChannelSamplingTime(ADC1, LL_ADC_CHANNEL_1, LL_ADC_SAMPLINGTIME_2CYCLES_5);
  LL_ADC_SetChannelSamplingTime(ADC1, LL_ADC_CHANNEL_2, LL_ADC_SAMPLINGTIME_2CYCLES_5);
  LL_ADC_SetChannelSamplingTime(ADC1, LL_ADC_CHANNEL_3, LL_ADC_SAMPLINGTIME_2CYCLES_5);
  LL_ADC_SetChannelSamplingTime(ADC1, LL_ADC_CHANNEL_4, LL_ADC_SAMPLINGTIME_2CYCLES_5);
  LL_ADC_SetChannelSamplingTime(ADC1, LL_ADC_CHANNEL_5, LL_ADC_SAMPLINGTIME_12CYCLES_5);
  LL_ADC_SetChannelSamplingTime(ADC1, LL_ADC_CHANNEL_7, LL_ADC_SAMPLINGTIME_24CYCLES_5);
  LL_ADC_SetChannelSamplingTime(ADC1, LL_ADC_CHANNEL_8, LL_ADC_SAMPLINGTIME_47CYCLES_5);
  LL_ADC_SetChannelSamplingTime(ADC1, LL_ADC_CHANNEL_11, LL_ADC_SAMPLINGTIME_47CYCLES_5);
  LL_ADC_SetChannelSamplingTime(ADC1, LL_ADC_CHANNEL_16, LL_ADC_SAMPLINGTIME_47CYCLES_5);

  //startovanje
  HAL_ADC_Start_DMA(&hadc1, pv1_buffer, 40);
  HAL_TIM_PWM_Start(&htim1, TIM_CHANNEL_1);
  HAL_TIMEx_PWMN_Start(&htim1, TIM_CHANNEL_1);
  HAL_TIM_PWM_Start(&htim1, TIM_CHANNEL_2);
  HAL_TIMEx_PWMN_Start(&htim1, TIM_CHANNEL_2);
  HAL_TIM_PWM_Start(&htim1, TIM_CHANNEL_3);
  HAL_TIMEx_PWMN_Start(&htim1, TIM_CHANNEL_3);
  HAL_TIM_PWM_Start(&htim8, TIM_CHANNEL_1);
  HAL_TIMEx_PWMN_Start(&htim8, TIM_CHANNEL_1);
  HAL_TIM_PWM_Start(&htim8, TIM_CHANNEL_2);
  HAL_TIMEx_PWMN_Start(&htim8, TIM_CHANNEL_2);
  HAL_TIM_PWM_Start(&htim8, TIM_CHANNEL_3);
  HAL_TIMEx_PWMN_Start(&htim8, TIM_CHANNEL_3);

  /* USER CODE END 2 */

  /* Infinite loop */
  while (1)
  {

  }
}

void SystemClock_Config(void)
{
  RCC_OscInitTypeDef RCC_OscInitStruct = {0};
  RCC_ClkInitTypeDef RCC_ClkInitStruct = {0};
  RCC_PeriphCLKInitTypeDef PeriphClkInit = {0};

  /** Configure the main internal regulator output voltage
  */
  if (HAL_PWREx_ControlVoltageScaling(PWR_REGULATOR_VOLTAGE_SCALE1_BOOST) != HAL_OK)
  {
    Error_Handler();
  }
  /** Initializes the CPU, AHB and APB busses clocks
  */
  RCC_OscInitStruct.OscillatorType = RCC_OSCILLATORTYPE_MSI;
  RCC_OscInitStruct.MSIState = RCC_MSI_ON;
  RCC_OscInitStruct.MSICalibrationValue = 0;
  RCC_OscInitStruct.MSIClockRange = RCC_MSIRANGE_6;
  RCC_OscInitStruct.PLL.PLLState = RCC_PLL_ON;
  RCC_OscInitStruct.PLL.PLLSource = RCC_PLLSOURCE_MSI;
  RCC_OscInitStruct.PLL.PLLM = 1;
  RCC_OscInitStruct.PLL.PLLN = 60;
  RCC_OscInitStruct.PLL.PLLP = RCC_PLLP_DIV2;
  RCC_OscInitStruct.PLL.PLLQ = RCC_PLLQ_DIV2;
  RCC_OscInitStruct.PLL.PLLR = RCC_PLLR_DIV2;
  if (HAL_RCC_OscConfig(&RCC_OscInitStruct) != HAL_OK)
  {
    Error_Handler();
  }
  /** Initializes the CPU, AHB and APB busses clocks
  */
  RCC_ClkInitStruct.ClockType = RCC_CLOCKTYPE_HCLK|RCC_CLOCKTYPE_SYSCLK
                              |RCC_CLOCKTYPE_PCLK1|RCC_CLOCKTYPE_PCLK2;
  RCC_ClkInitStruct.SYSCLKSource = RCC_SYSCLKSOURCE_PLLCLK;
  RCC_ClkInitStruct.AHBCLKDivider = RCC_SYSCLK_DIV1;
  RCC_ClkInitStruct.APB1CLKDivider = RCC_HCLK_DIV1;
  RCC_ClkInitStruct.APB2CLKDivider = RCC_HCLK_DIV1;

  if (HAL_RCC_ClockConfig(&RCC_ClkInitStruct, FLASH_LATENCY_5) != HAL_OK)
  {
    Error_Handler();
  }
  PeriphClkInit.PeriphClockSelection = RCC_PERIPHCLK_ADC;
  PeriphClkInit.AdcClockSelection = RCC_ADCCLKSOURCE_PLLSAI1;
  PeriphClkInit.PLLSAI1.PLLSAI1Source = RCC_PLLSOURCE_MSI;
  PeriphClkInit.PLLSAI1.PLLSAI1M = 1;
  PeriphClkInit.PLLSAI1.PLLSAI1N = 37;
  PeriphClkInit.PLLSAI1.PLLSAI1P = RCC_PLLP_DIV2;
  PeriphClkInit.PLLSAI1.PLLSAI1Q = RCC_PLLQ_DIV2;
  PeriphClkInit.PLLSAI1.PLLSAI1R = RCC_PLLR_DIV2;
  PeriphClkInit.PLLSAI1.PLLSAI1ClockOut = RCC_PLLSAI1_ADC1CLK;
  if (HAL_RCCEx_PeriphCLKConfig(&PeriphClkInit) != HAL_OK)
  {
    Error_Handler();
  }
}

static void MX_ADC1_Init(void)
{

  ADC_ChannelConfTypeDef sConfig = {0};

  /** Common config
  */
  hadc1.Instance = ADC1;
  hadc1.Init.ClockPrescaler = ADC_CLOCK_ASYNC_DIV1;
  hadc1.Init.Resolution = ADC_RESOLUTION_12B;
  hadc1.Init.DataAlign = ADC_DATAALIGN_RIGHT;
  hadc1.Init.ScanConvMode = ADC_SCAN_ENABLE;
  hadc1.Init.EOCSelection = ADC_EOC_SEQ_CONV;
  hadc1.Init.LowPowerAutoWait = DISABLE;
  hadc1.Init.ContinuousConvMode = ENABLE;
  hadc1.Init.NbrOfConversion = 5;
  hadc1.Init.DiscontinuousConvMode = DISABLE;
  hadc1.Init.ExternalTrigConv = ADC_EXTERNALTRIG_T1_TRGO2;
  hadc1.Init.ExternalTrigConvEdge = ADC_EXTERNALTRIGCONVEDGE_RISING;
  hadc1.Init.DMAContinuousRequests = DISABLE;
  hadc1.Init.Overrun = ADC_OVR_DATA_OVERWRITTEN;
  hadc1.Init.OversamplingMode = DISABLE;
  if (HAL_ADC_Init(&hadc1) != HAL_OK)
  {
    Error_Handler();
  }
  /** Configure Regular Channel
  */
  sConfig.Channel = ADC_CHANNEL_4;
  sConfig.Rank = ADC_REGULAR_RANK_1;
  sConfig.SamplingTime = ADC_SAMPLETIME_2CYCLES_5;
  sConfig.SingleDiff = ADC_SINGLE_ENDED;
  sConfig.OffsetNumber = ADC_OFFSET_NONE;
  sConfig.Offset = 0;
  if (HAL_ADC_ConfigChannel(&hadc1, &sConfig) != HAL_OK)
  {
    Error_Handler();
  }
  /** Configure Regular Channel
  */
  sConfig.Channel = ADC_CHANNEL_2;
  sConfig.Rank = ADC_REGULAR_RANK_2;
  if (HAL_ADC_ConfigChannel(&hadc1, &sConfig) != HAL_OK)
  {
    Error_Handler();
  }
  /** Configure Regular Channel
  */
  sConfig.Channel = ADC_CHANNEL_5;
  sConfig.Rank = ADC_REGULAR_RANK_3;
  sConfig.SamplingTime = ADC_SAMPLETIME_6CYCLES_5;
  if (HAL_ADC_ConfigChannel(&hadc1, &sConfig) != HAL_OK)
  {
    Error_Handler();
  }
  /** Configure Regular Channel
  */
  sConfig.Channel = ADC_CHANNEL_3;
  sConfig.Rank = ADC_REGULAR_RANK_4;
  if (HAL_ADC_ConfigChannel(&hadc1, &sConfig) != HAL_OK)
  {
    Error_Handler();
  }
  /** Configure Regular Channel
  */
  sConfig.Channel = ADC_CHANNEL_1;
  sConfig.Rank = ADC_REGULAR_RANK_5;
  if (HAL_ADC_ConfigChannel(&hadc1, &sConfig) != HAL_OK)
  {
    Error_Handler();
  }

}

static void MX_TIM1_Init(void)
{

  TIM_ClockConfigTypeDef sClockSourceConfig = {0};
  TIM_MasterConfigTypeDef sMasterConfig = {0};
  TIM_OC_InitTypeDef sConfigOC = {0};
  TIM_BreakDeadTimeConfigTypeDef sBreakDeadTimeConfig = {0};

  htim1.Instance = TIM1;
  htim1.Init.Prescaler = 0;
  htim1.Init.CounterMode = TIM_COUNTERMODE_CENTERALIGNED2;
  htim1.Init.Period = 200;
  htim1.Init.ClockDivision = TIM_CLOCKDIVISION_DIV1;
  htim1.Init.RepetitionCounter = 0;
  htim1.Init.AutoReloadPreload = TIM_AUTORELOAD_PRELOAD_ENABLE;
  if (HAL_TIM_Base_Init(&htim1) != HAL_OK)
  {
    Error_Handler();
  }
  sClockSourceConfig.ClockSource = TIM_CLOCKSOURCE_INTERNAL;
  if (HAL_TIM_ConfigClockSource(&htim1, &sClockSourceConfig) != HAL_OK)
  {
    Error_Handler();
  }
  if (HAL_TIM_PWM_Init(&htim1) != HAL_OK)
  {
    Error_Handler();
  }
  sMasterConfig.MasterOutputTrigger = TIM_TRGO_RESET;
  sMasterConfig.MasterOutputTrigger2 = TIM_TRGO2_UPDATE;
  sMasterConfig.MasterSlaveMode = TIM_MASTERSLAVEMODE_DISABLE;
  if (HAL_TIMEx_MasterConfigSynchronization(&htim1, &sMasterConfig) != HAL_OK)
  {
    Error_Handler();
  }
  sConfigOC.OCMode = TIM_OCMODE_PWM1;
  sConfigOC.Pulse = 40;
  sConfigOC.OCPolarity = TIM_OCPOLARITY_HIGH;
  sConfigOC.OCNPolarity = TIM_OCNPOLARITY_HIGH;
  sConfigOC.OCFastMode = TIM_OCFAST_ENABLE;
  sConfigOC.OCIdleState = TIM_OCIDLESTATE_RESET;
  sConfigOC.OCNIdleState = TIM_OCNIDLESTATE_RESET;
  if (HAL_TIM_PWM_ConfigChannel(&htim1, &sConfigOC, TIM_CHANNEL_1) != HAL_OK)
  {
    Error_Handler();
  }
  sConfigOC.Pulse = 160;
  if (HAL_TIM_PWM_ConfigChannel(&htim1, &sConfigOC, TIM_CHANNEL_2) != HAL_OK)
  {
    Error_Handler();
  }
  sConfigOC.Pulse = 110;
  if (HAL_TIM_PWM_ConfigChannel(&htim1, &sConfigOC, TIM_CHANNEL_3) != HAL_OK)
  {
    Error_Handler();
  }
  sBreakDeadTimeConfig.OffStateRunMode = TIM_OSSR_DISABLE;
  sBreakDeadTimeConfig.OffStateIDLEMode = TIM_OSSI_DISABLE;
  sBreakDeadTimeConfig.LockLevel = TIM_LOCKLEVEL_OFF;
  sBreakDeadTimeConfig.DeadTime = 12;
  sBreakDeadTimeConfig.BreakState = TIM_BREAK_DISABLE;
  sBreakDeadTimeConfig.BreakPolarity = TIM_BREAKPOLARITY_HIGH;
  sBreakDeadTimeConfig.BreakFilter = 0;
  sBreakDeadTimeConfig.Break2State = TIM_BREAK2_DISABLE;
  sBreakDeadTimeConfig.Break2Polarity = TIM_BREAK2POLARITY_HIGH;
  sBreakDeadTimeConfig.Break2Filter = 0;
  sBreakDeadTimeConfig.AutomaticOutput = TIM_AUTOMATICOUTPUT_DISABLE;
  if (HAL_TIMEx_ConfigBreakDeadTime(&htim1, &sBreakDeadTimeConfig) != HAL_OK)
  {
    Error_Handler();
  }
  HAL_TIM_MspPostInit(&htim1);

}

static void MX_TIM8_Init(void)
{

  TIM_MasterConfigTypeDef sMasterConfig = {0};
  TIM_OC_InitTypeDef sConfigOC = {0};
  TIM_BreakDeadTimeConfigTypeDef sBreakDeadTimeConfig = {0};

  htim8.Instance = TIM8;
  htim8.Init.Prescaler = 0;
  htim8.Init.CounterMode = TIM_COUNTERMODE_CENTERALIGNED2;
  htim8.Init.Period = 200;
  htim8.Init.ClockDivision = TIM_CLOCKDIVISION_DIV1;
  htim8.Init.RepetitionCounter = 0;
  htim8.Init.AutoReloadPreload = TIM_AUTORELOAD_PRELOAD_ENABLE;
  if (HAL_TIM_PWM_Init(&htim8) != HAL_OK)
  {
    Error_Handler();
  }
  sMasterConfig.MasterOutputTrigger = TIM_TRGO_RESET;
  sMasterConfig.MasterOutputTrigger2 = TIM_TRGO2_RESET;
  sMasterConfig.MasterSlaveMode = TIM_MASTERSLAVEMODE_DISABLE;
  if (HAL_TIMEx_MasterConfigSynchronization(&htim8, &sMasterConfig) != HAL_OK)
  {
    Error_Handler();
  }
  sConfigOC.OCMode = TIM_OCMODE_PWM1;
  sConfigOC.Pulse = 150;
  sConfigOC.OCPolarity = TIM_OCPOLARITY_HIGH;
  sConfigOC.OCNPolarity = TIM_OCNPOLARITY_HIGH;
  sConfigOC.OCFastMode = TIM_OCFAST_ENABLE;
  sConfigOC.OCIdleState = TIM_OCIDLESTATE_RESET;
  sConfigOC.OCNIdleState = TIM_OCNIDLESTATE_RESET;
  if (HAL_TIM_PWM_ConfigChannel(&htim8, &sConfigOC, TIM_CHANNEL_1) != HAL_OK)
  {
    Error_Handler();
  }
  sConfigOC.Pulse = 250;
  if (HAL_TIM_PWM_ConfigChannel(&htim8, &sConfigOC, TIM_CHANNEL_2) != HAL_OK)
  {
    Error_Handler();
  }
  sConfigOC.Pulse = 167;
  if (HAL_TIM_PWM_ConfigChannel(&htim8, &sConfigOC, TIM_CHANNEL_3) != HAL_OK)
  {
    Error_Handler();
  }
  sBreakDeadTimeConfig.OffStateRunMode = TIM_OSSR_DISABLE;
  sBreakDeadTimeConfig.OffStateIDLEMode = TIM_OSSI_DISABLE;
  sBreakDeadTimeConfig.LockLevel = TIM_LOCKLEVEL_OFF;
  sBreakDeadTimeConfig.DeadTime = 12;
  sBreakDeadTimeConfig.BreakState = TIM_BREAK_DISABLE;
  sBreakDeadTimeConfig.BreakPolarity = TIM_BREAKPOLARITY_HIGH;
  sBreakDeadTimeConfig.BreakFilter = 0;
  sBreakDeadTimeConfig.Break2State = TIM_BREAK2_DISABLE;
  sBreakDeadTimeConfig.Break2Polarity = TIM_BREAK2POLARITY_HIGH;
  sBreakDeadTimeConfig.Break2Filter = 0;
  sBreakDeadTimeConfig.AutomaticOutput = TIM_AUTOMATICOUTPUT_DISABLE;
  if (HAL_TIMEx_ConfigBreakDeadTime(&htim8, &sBreakDeadTimeConfig) != HAL_OK)
  {
    Error_Handler();
  }
  HAL_TIM_MspPostInit(&htim8);

}

static void MX_DMA_Init(void)
{

  /* DMA controller clock enable */
  __HAL_RCC_DMAMUX1_CLK_ENABLE();
  __HAL_RCC_DMA1_CLK_ENABLE();

  /* DMA interrupt init */
  /* DMA1_Channel1_IRQn interrupt configuration */
  HAL_NVIC_SetPriority(DMA1_Channel1_IRQn, 0, 0);
  HAL_NVIC_EnableIRQ(DMA1_Channel1_IRQn);
  /* DMAMUX1_OVR_IRQn interrupt configuration */
  HAL_NVIC_SetPriority(DMAMUX1_OVR_IRQn, 0, 0);
  HAL_NVIC_EnableIRQ(DMAMUX1_OVR_IRQn);

}

static void MX_GPIO_Init(void)
{
  GPIO_InitTypeDef GPIO_InitStruct = {0};

  /* GPIO Ports Clock Enable */
  __HAL_RCC_GPIOE_CLK_ENABLE();
  __HAL_RCC_GPIOC_CLK_ENABLE();
  __HAL_RCC_GPIOF_CLK_ENABLE();
  __HAL_RCC_GPIOH_CLK_ENABLE();
  __HAL_RCC_GPIOA_CLK_ENABLE();
  __HAL_RCC_GPIOB_CLK_ENABLE();
  __HAL_RCC_GPIOG_CLK_ENABLE();
  __HAL_RCC_GPIOD_CLK_ENABLE();
  HAL_PWREx_EnableVddIO2();

  /*Configure GPIO pin Output Level */
  HAL_GPIO_WritePin(GPIOC, GPIO_PIN_12, GPIO_PIN_RESET);

  /*Configure GPIO pins : PE2 PE3 PE4 PE5
                           PE6 PE7 PE14 PE15
                           PE0 PE1 */
  GPIO_InitStruct.Pin = GPIO_PIN_2|GPIO_PIN_3|GPIO_PIN_4|GPIO_PIN_5
                          |GPIO_PIN_6|GPIO_PIN_7|GPIO_PIN_14|GPIO_PIN_15
                          |GPIO_PIN_0|GPIO_PIN_1;
  GPIO_InitStruct.Mode = GPIO_MODE_ANALOG;
  GPIO_InitStruct.Pull = GPIO_NOPULL;
  HAL_GPIO_Init(GPIOE, &GPIO_InitStruct);

  /*Configure GPIO pins : PC13 PC14 PC15 PC4
                           PC5 PC9 PC10 PC11 */
  GPIO_InitStruct.Pin = GPIO_PIN_13|GPIO_PIN_14|GPIO_PIN_15|GPIO_PIN_4
                          |GPIO_PIN_5|GPIO_PIN_9|GPIO_PIN_10|GPIO_PIN_11;
  GPIO_InitStruct.Mode = GPIO_MODE_ANALOG;
  GPIO_InitStruct.Pull = GPIO_NOPULL;
  HAL_GPIO_Init(GPIOC, &GPIO_InitStruct);

  /*Configure GPIO pins : PF0 PF1 PF2 PF3
                           PF4 PF5 PF6 PF7
                           PF8 PF9 PF10 PF11
                           PF12 PF13 PF14 PF15 */
  GPIO_InitStruct.Pin = GPIO_PIN_0|GPIO_PIN_1|GPIO_PIN_2|GPIO_PIN_3
                          |GPIO_PIN_4|GPIO_PIN_5|GPIO_PIN_6|GPIO_PIN_7
                          |GPIO_PIN_8|GPIO_PIN_9|GPIO_PIN_10|GPIO_PIN_11
                          |GPIO_PIN_12|GPIO_PIN_13|GPIO_PIN_14|GPIO_PIN_15;
  GPIO_InitStruct.Mode = GPIO_MODE_ANALOG;
  GPIO_InitStruct.Pull = GPIO_NOPULL;
  HAL_GPIO_Init(GPIOF, &GPIO_InitStruct);

  /*Configure GPIO pins : PH0 PH1 PH3 */
  GPIO_InitStruct.Pin = GPIO_PIN_0|GPIO_PIN_1|GPIO_PIN_3;
  GPIO_InitStruct.Mode = GPIO_MODE_ANALOG;
  GPIO_InitStruct.Pull = GPIO_NOPULL;
  HAL_GPIO_Init(GPIOH, &GPIO_InitStruct);

  /*Configure GPIO pins : PA7 PA8 PA9 PA10
                           PA11 PA12 PA15 */
  GPIO_InitStruct.Pin = GPIO_PIN_7|GPIO_PIN_8|GPIO_PIN_9|GPIO_PIN_10
                          |GPIO_PIN_11|GPIO_PIN_12|GPIO_PIN_15;
  GPIO_InitStruct.Mode = GPIO_MODE_ANALOG;
  GPIO_InitStruct.Pull = GPIO_NOPULL;
  HAL_GPIO_Init(GPIOA, &GPIO_InitStruct);

  /*Configure GPIO pins : PB2 PB10 PB12 PB13
                           PB4 PB5 PB6 PB7
                           PB8 PB9 */
  GPIO_InitStruct.Pin = GPIO_PIN_2|GPIO_PIN_10|GPIO_PIN_12|GPIO_PIN_13
                          |GPIO_PIN_4|GPIO_PIN_5|GPIO_PIN_6|GPIO_PIN_7
                          |GPIO_PIN_8|GPIO_PIN_9;
  GPIO_InitStruct.Mode = GPIO_MODE_ANALOG;
  GPIO_InitStruct.Pull = GPIO_NOPULL;
  HAL_GPIO_Init(GPIOB, &GPIO_InitStruct);

  /*Configure GPIO pins : PG0 PG1 PG2 PG3
                           PG4 PG5 PG6 PG7
                           PG8 PG9 PG10 PG11
                           PG12 PG13 PG14 */
  GPIO_InitStruct.Pin = GPIO_PIN_0|GPIO_PIN_1|GPIO_PIN_2|GPIO_PIN_3
                          |GPIO_PIN_4|GPIO_PIN_5|GPIO_PIN_6|GPIO_PIN_7
                          |GPIO_PIN_8|GPIO_PIN_9|GPIO_PIN_10|GPIO_PIN_11
                          |GPIO_PIN_12|GPIO_PIN_13|GPIO_PIN_14;
  GPIO_InitStruct.Mode = GPIO_MODE_ANALOG;
  GPIO_InitStruct.Pull = GPIO_NOPULL;
  HAL_GPIO_Init(GPIOG, &GPIO_InitStruct);

  /*Configure GPIO pins : PD8 PD9 PD10 PD11
                           PD12 PD13 PD14 PD15
                           PD0 PD1 PD2 PD3
                           PD4 PD5 PD6 PD7 */
  GPIO_InitStruct.Pin = GPIO_PIN_8|GPIO_PIN_9|GPIO_PIN_10|GPIO_PIN_11
                          |GPIO_PIN_12|GPIO_PIN_13|GPIO_PIN_14|GPIO_PIN_15
                          |GPIO_PIN_0|GPIO_PIN_1|GPIO_PIN_2|GPIO_PIN_3
                          |GPIO_PIN_4|GPIO_PIN_5|GPIO_PIN_6|GPIO_PIN_7;
  GPIO_InitStruct.Mode = GPIO_MODE_ANALOG;
  GPIO_InitStruct.Pull = GPIO_NOPULL;
  HAL_GPIO_Init(GPIOD, &GPIO_InitStruct);

  /*Configure GPIO pin : PC12 */
  GPIO_InitStruct.Pin = GPIO_PIN_12;
  GPIO_InitStruct.Mode = GPIO_MODE_OUTPUT_PP;
  GPIO_InitStruct.Pull = GPIO_NOPULL;
  GPIO_InitStruct.Speed = GPIO_SPEED_FREQ_VERY_HIGH;
  HAL_GPIO_Init(GPIOC, &GPIO_InitStruct);

}

void Error_Handler(void)
{
}

/************************ (C) COPYRIGHT STMicroelectronics *****END OF FILE****/
